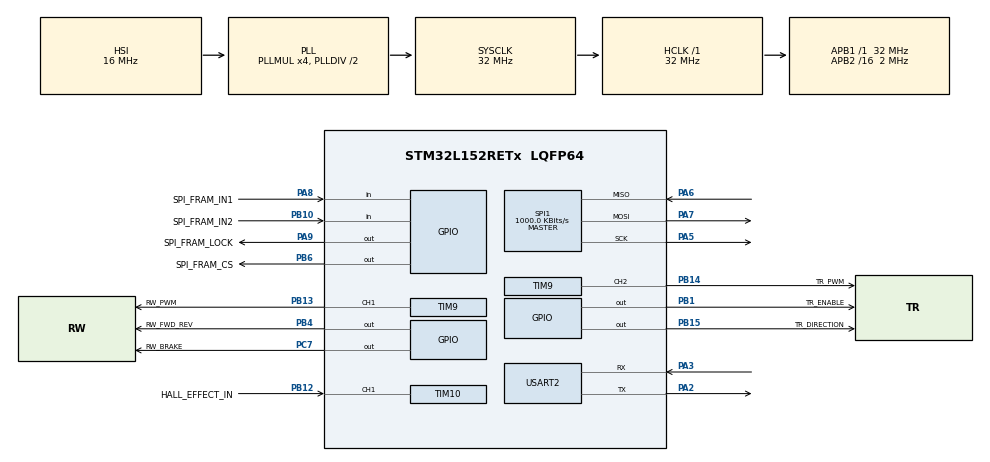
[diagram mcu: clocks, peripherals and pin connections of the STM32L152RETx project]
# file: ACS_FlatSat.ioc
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Mcu.Family=STM32L1
Mcu.Name=STM32L152RETx
Mcu.Package=LQFP64
NVIC.PriorityGroup=NVIC_PRIORITYGROUP_0
PA2.Mode=Asynchronous
PA2.Signal=USART2_TX
PA3.Mode=Asynchronous
PA3.Signal=USART2_RX
PA5.Mode=Full_Duplex_Master
PA5.Signal=SPI1_SCK
PA6.Mode=Full_Duplex_Master
PA6.Signal=SPI1_MISO
PA7.Mode=Full_Duplex_Master
PA7.Signal=SPI1_MOSI
PA8.GPIO_Label=SPI_FRAM_IN1
PA8.Signal=GPIO_Input
PA9.GPIO_Label=SPI_FRAM_LOCK
PA9.Signal=GPIO_Output
PB1.GPIO_Label=TR_ENABLE
PB1.Signal=GPIO_Output
PB10.GPIO_Label=SPI_FRAM_IN2
PB10.Signal=GPIO_Input
PB12.GPIO_Label=HALL_EFFECT_IN
PB12.Signal=S_TIM10_CH1
PB13.GPIO_Label=RW_PWM
PB13.Signal=S_TIM9_CH1
PB14.GPIO_Label=TR_PWM
PB14.Signal=S_TIM9_CH2
PB15.GPIO_Label=TR_DIRECTION
PB15.Signal=GPIO_Output
PB4.GPIO_Label=RW_FWD_REV
PB4.Signal=GPIO_Output
PB6.GPIO_Label=SPI_FRAM_CS
PB6.Signal=GPIO_Output
PC7.GPIO_Label=RW_BRAKE
PC7.Signal=GPIO_Output
ProjectManager.HeapSize=0x2000
ProjectManager.StackSize=0x400
ProjectManager.TargetToolchain=TrueSTUDIO
RCC.48MHZClocksFreq_Value=32000000
RCC.AHBFreq_Value=32000000
RCC.APB1Freq_Value=32000000
RCC.APB1TimFreq_Value=32000000
RCC.APB2CLKDivider=RCC_HCLK_DIV16
RCC.APB2Freq_Value=2000000
RCC.APB2TimFreq_Value=4000000
RCC.HCLKFreq_Value=32000000
RCC.HSE_VALUE=8000000
RCC.HSI_VALUE=16000000
RCC.LSE_VALUE=32768
RCC.MSI_VALUE=2097000
RCC.PLLMUL=RCC_PLL_MUL4
RCC.RTCClockSelectionVirtual=RCC_RTCCLKSOURCE_LSE
RCC.SYSCLKFreq_VALUE=32000000
RCC.SYSCLKSource=RCC_SYSCLKSOURCE_PLLCLK
RCC.USBOutput=48000000
RCC.VCOOutputFreq_Value=64000000
SH.S_TIM10_CH1.0=TIM10_CH1,Input_Capture1_from_TI1
SH.S_TIM9_CH1.0=TIM9_CH1,PWM Generation1 CH1
SH.S_TIM9_CH2.0=TIM9_CH2,PWM Generation2 CH2
SPI1.CalculateBaudRate=1000.0 KBits/s
SPI1.Direction=SPI_DIRECTION_2LINES
SPI1.Mode=SPI_MODE_MASTER
SPI1.VirtualType=VM_MASTER
TIM10.Channel=TIM_CHANNEL_1
TIM10.ClockDivision=TIM_CLOCKDIVISION_DIV4
TIM10.ICPolarity_CH1=TIM_INPUTCHANNELPOLARITY_BOTHEDGE
TIM10.Period=65535
TIM9.Channel-PWM\ Generation1\ CH1=TIM_CHANNEL_1
TIM9.Channel-PWM\ Generation2\ CH2=TIM_CHANNEL_2
TIM9.ClockDivision=TIM_CLOCKDIVISION_DIV4
TIM9.Period=1000
TIM9.Pulse-PWM\ Generation1\ CH1=0
TIM9.Pulse-PWM\ Generation2\ CH2=0
USART2.OverSampling=UART_OVERSAMPLING_16
USART2.VirtualMode=VM_ASYNC
VP_TIM10_VS_ClockSourceINT.Mode=Internal
VP_TIM9_VS_ClockSourceINT.Mode=Internal
board=NUCLEO-L152RE

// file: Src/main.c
/* USER CODE BEGIN Header */
/**
  ******************************************************************************
  * @file           : main.c
  * @brief          : Main program body
  ******************************************************************************
  * @attention
  *
  * <h2><center>&copy; Copyright (c) 2019 STMicroelectronics.
  * All rights reserved.</center></h2>
  *
  * This software component is licensed by ST under BSD 3-Clause license,
  * the "License"; You may not use this file except in compliance with the
  * License. You may obtain a copy of the License at:
  *                        opensource.org/licenses/BSD-3-Clause
  *
  ******************************************************************************
  */
/* USER CODE END Header */

#include "main.h"

/* USER CODE BEGIN Includes */
#include <ACSStateMachine.h>
#include <string.h>
/* USER CODE END Includes */

SPI_HandleTypeDef hspi1;

TIM_HandleTypeDef htim9;
TIM_HandleTypeDef htim10;

UART_HandleTypeDef huart2;

void SystemClock_Config(void);
static void MX_GPIO_Init(void);
static void MX_USART2_UART_Init(void);
static void MX_SPI1_Init(void);
static void MX_TIM9_Init(void);
static void MX_TIM10_Init(void);

int main(void)
{

  /* MCU Configuration--------------------------------------------------------*/

  /* Reset of all peripherals, Initializes the Flash interface and the Systick. */
  HAL_Init();

  /* Configure the system clock */
  SystemClock_Config();

  /* Initialize all configured peripherals */
  MX_GPIO_Init();
  MX_USART2_UART_Init();
  MX_SPI1_Init();
  MX_TIM9_Init();
  MX_TIM10_Init();
  /* USER CODE BEGIN 2 */

  #ifdef ENABLE_ACTUATORS
  initActuators(&htim9, &htim10);
  rw_init(RW_FWD_REV_Pin, RW_FWD_REV_GPIO_Port, RW_BRAKE_Pin, RW_BRAKE_GPIO_Port);
  tr_init(TR_DIRECTION_Pin, TR_DIRECTION_GPIO_Port, TR_ENABLE_Pin, TR_ENABLE_GPIO_Port);
  #endif
  #ifdef ENABLE_42
  setUartHandle(&huart2);
  #endif
  #ifdef ENABLE_FRAM
  setSpiHandle(&hspi1);
  #endif
  runACS();

  /* USER CODE END 2 */

  /* Infinite loop */
  while (1)
  {

  }
}

void SystemClock_Config(void)
{
  RCC_OscInitTypeDef RCC_OscInitStruct = {0};
  RCC_ClkInitTypeDef RCC_ClkInitStruct = {0};

  /** Configure the main internal regulator output voltage
  */
  __HAL_PWR_VOLTAGESCALING_CONFIG(PWR_REGULATOR_VOLTAGE_SCALE1);
  /** Initializes the CPU, AHB and APB busses clocks
  */
  RCC_OscInitStruct.OscillatorType = RCC_OSCILLATORTYPE_HSI;
  RCC_OscInitStruct.HSIState = RCC_HSI_ON;
  RCC_OscInitStruct.HSICalibrationValue = RCC_HSICALIBRATION_DEFAULT;
  RCC_OscInitStruct.PLL.PLLState = RCC_PLL_ON;
  RCC_OscInitStruct.PLL.PLLSource = RCC_PLLSOURCE_HSI;
  RCC_OscInitStruct.PLL.PLLMUL = RCC_PLL_MUL4;
  RCC_OscInitStruct.PLL.PLLDIV = RCC_PLL_DIV2;
  if (HAL_RCC_OscConfig(&RCC_OscInitStruct) != HAL_OK)
  {
    Error_Handler();
  }
  /** Initializes the CPU, AHB and APB busses clocks
  */
  RCC_ClkInitStruct.ClockType = RCC_CLOCKTYPE_HCLK|RCC_CLOCKTYPE_SYSCLK
                              |RCC_CLOCKTYPE_PCLK1|RCC_CLOCKTYPE_PCLK2;
  RCC_ClkInitStruct.SYSCLKSource = RCC_SYSCLKSOURCE_PLLCLK;
  RCC_ClkInitStruct.AHBCLKDivider = RCC_SYSCLK_DIV1;
  RCC_ClkInitStruct.APB1CLKDivider = RCC_HCLK_DIV1;
  RCC_ClkInitStruct.APB2CLKDivider = RCC_HCLK_DIV16;

  if (HAL_RCC_ClockConfig(&RCC_ClkInitStruct, FLASH_LATENCY_1) != HAL_OK)
  {
    Error_Handler();
  }
}

static void MX_SPI1_Init(void)
{

  /* SPI1 parameter configuration*/
  hspi1.Instance = SPI1;
  hspi1.Init.Mode = SPI_MODE_MASTER;
  hspi1.Init.Direction = SPI_DIRECTION_2LINES;
  hspi1.Init.DataSize = SPI_DATASIZE_8BIT;
  hspi1.Init.CLKPolarity = SPI_POLARITY_LOW;
  hspi1.Init.CLKPhase = SPI_PHASE_1EDGE;
  hspi1.Init.NSS = SPI_NSS_SOFT;
  hspi1.Init.BaudRatePrescaler = SPI_BAUDRATEPRESCALER_2;
  hspi1.Init.FirstBit = SPI_FIRSTBIT_MSB;
  hspi1.Init.TIMode = SPI_TIMODE_DISABLE;
  hspi1.Init.CRCCalculation = SPI_CRCCALCULATION_DISABLE;
  hspi1.Init.CRCPolynomial = 10;
  if (HAL_SPI_Init(&hspi1) != HAL_OK)
  {
    Error_Handler();
  }

}

static void MX_TIM9_Init(void)
{

  TIM_ClockConfigTypeDef sClockSourceConfig = {0};
  TIM_MasterConfigTypeDef sMasterConfig = {0};
  TIM_OC_InitTypeDef sConfigOC = {0};

  htim9.Instance = TIM9;
  htim9.Init.Prescaler = 0;
  htim9.Init.CounterMode = TIM_COUNTERMODE_UP;
  htim9.Init.Period = 1000;
  htim9.Init.ClockDivision = TIM_CLOCKDIVISION_DIV4;
  if (HAL_TIM_Base_Init(&htim9) != HAL_OK)
  {
    Error_Handler();
  }
  sClockSourceConfig.ClockSource = TIM_CLOCKSOURCE_INTERNAL;
  if (HAL_TIM_ConfigClockSource(&htim9, &sClockSourceConfig) != HAL_OK)
  {
    Error_Handler();
  }
  if (HAL_TIM_PWM_Init(&htim9) != HAL_OK)
  {
    Error_Handler();
  }
  sMasterConfig.MasterOutputTrigger = TIM_TRGO_RESET;
  sMasterConfig.MasterSlaveMode = TIM_MASTERSLAVEMODE_DISABLE;
  if (HAL_TIMEx_MasterConfigSynchronization(&htim9, &sMasterConfig) != HAL_OK)
  {
    Error_Handler();
  }
  sConfigOC.OCMode = TIM_OCMODE_PWM1;
  sConfigOC.Pulse = 0;
  sConfigOC.OCPolarity = TIM_OCPOLARITY_HIGH;
  sConfigOC.OCFastMode = TIM_OCFAST_DISABLE;
  if (HAL_TIM_PWM_ConfigChannel(&htim9, &sConfigOC, TIM_CHANNEL_1) != HAL_OK)
  {
    Error_Handler();
  }
  if (HAL_TIM_PWM_ConfigChannel(&htim9, &sConfigOC, TIM_CHANNEL_2) != HAL_OK)
  {
    Error_Handler();
  }
  HAL_TIM_MspPostInit(&htim9);

}

static void MX_TIM10_Init(void)
{

  TIM_ClockConfigTypeDef sClockSourceConfig = {0};
  TIM_IC_InitTypeDef sConfigIC = {0};

  htim10.Instance = TIM10;
  htim10.Init.Prescaler = 0;
  htim10.Init.CounterMode = TIM_COUNTERMODE_UP;
  htim10.Init.Period = 65535;
  htim10.Init.ClockDivision = TIM_CLOCKDIVISION_DIV4;
  if (HAL_TIM_Base_Init(&htim10) != HAL_OK)
  {
    Error_Handler();
  }
  sClockSourceConfig.ClockSource = TIM_CLOCKSOURCE_INTERNAL;
  if (HAL_TIM_ConfigClockSource(&htim10, &sClockSourceConfig) != HAL_OK)
  {
    Error_Handler();
  }
  if (HAL_TIM_IC_Init(&htim10) != HAL_OK)
  {
    Error_Handler();
  }
  sConfigIC.ICPolarity = TIM_INPUTCHANNELPOLARITY_BOTHEDGE;
  sConfigIC.ICSelection = TIM_ICSELECTION_DIRECTTI;
  sConfigIC.ICPrescaler = TIM_ICPSC_DIV1;
  sConfigIC.ICFilter = 0;
  if (HAL_TIM_IC_ConfigChannel(&htim10, &sConfigIC, TIM_CHANNEL_1) != HAL_OK)
  {
    Error_Handler();
  }

}

static void MX_USART2_UART_Init(void)
{

  huart2.Instance = USART2;
  huart2.Init.BaudRate = 115200;
  huart2.Init.WordLength = UART_WORDLENGTH_8B;
  huart2.Init.StopBits = UART_STOPBITS_1;
  huart2.Init.Parity = UART_PARITY_NONE;
  huart2.Init.Mode = UART_MODE_TX_RX;
  huart2.Init.HwFlowCtl = UART_HWCONTROL_NONE;
  huart2.Init.OverSampling = UART_OVERSAMPLING_16;
  if (HAL_UART_Init(&huart2) != HAL_OK)
  {
    Error_Handler();
  }

}

static void MX_GPIO_Init(void)
{
  GPIO_InitTypeDef GPIO_InitStruct = {0};

  /* GPIO Ports Clock Enable */
  __HAL_RCC_GPIOA_CLK_ENABLE();
  __HAL_RCC_GPIOB_CLK_ENABLE();
  __HAL_RCC_GPIOC_CLK_ENABLE();

  /*Configure GPIO pin Output Level */
  HAL_GPIO_WritePin(GPIOB, TR_ENABLE_Pin|TR_DIRECTION_Pin|RW_FWD_REV_Pin|SPI_FRAM_CS_Pin, GPIO_PIN_RESET);

  /*Configure GPIO pin Output Level */
  HAL_GPIO_WritePin(RW_BRAKE_GPIO_Port, RW_BRAKE_Pin, GPIO_PIN_RESET);

  /*Configure GPIO pin Output Level */
  HAL_GPIO_WritePin(SPI_FRAM_LOCK_GPIO_Port, SPI_FRAM_LOCK_Pin, GPIO_PIN_RESET);

  /*Configure GPIO pins : TR_ENABLE_Pin TR_DIRECTION_Pin RW_FWD_REV_Pin SPI_FRAM_CS_Pin */
  GPIO_InitStruct.Pin = TR_ENABLE_Pin|TR_DIRECTION_Pin|RW_FWD_REV_Pin|SPI_FRAM_CS_Pin;
  GPIO_InitStruct.Mode = GPIO_MODE_OUTPUT_PP;
  GPIO_InitStruct.Pull = GPIO_NOPULL;
  GPIO_InitStruct.Speed = GPIO_SPEED_FREQ_LOW;
  HAL_GPIO_Init(GPIOB, &GPIO_InitStruct);

  /*Configure GPIO pin : SPI_FRAM_IN2_Pin */
  GPIO_InitStruct.Pin = SPI_FRAM_IN2_Pin;
  GPIO_InitStruct.Mode = GPIO_MODE_INPUT;
  GPIO_InitStruct.Pull = GPIO_NOPULL;
  HAL_GPIO_Init(SPI_FRAM_IN2_GPIO_Port, &GPIO_InitStruct);

  /*Configure GPIO pin : RW_BRAKE_Pin */
  GPIO_InitStruct.Pin = RW_BRAKE_Pin;
  GPIO_InitStruct.Mode = GPIO_MODE_OUTPUT_PP;
  GPIO_InitStruct.Pull = GPIO_NOPULL;
  GPIO_InitStruct.Speed = GPIO_SPEED_FREQ_LOW;
  HAL_GPIO_Init(RW_BRAKE_GPIO_Port, &GPIO_InitStruct);

  /*Configure GPIO pin : SPI_FRAM_IN1_Pin */
  GPIO_InitStruct.Pin = SPI_FRAM_IN1_Pin;
  GPIO_InitStruct.Mode = GPIO_MODE_INPUT;
  GPIO_InitStruct.Pull = GPIO_NOPULL;
  HAL_GPIO_Init(SPI_FRAM_IN1_GPIO_Port, &GPIO_InitStruct);

  /*Configure GPIO pin : SPI_FRAM_LOCK_Pin */
  GPIO_InitStruct.Pin = SPI_FRAM_LOCK_Pin;
  GPIO_InitStruct.Mode = GPIO_MODE_OUTPUT_PP;
  GPIO_InitStruct.Pull = GPIO_NOPULL;
  GPIO_InitStruct.Speed = GPIO_SPEED_FREQ_LOW;
  HAL_GPIO_Init(SPI_FRAM_LOCK_GPIO_Port, &GPIO_InitStruct);

}

void Error_Handler(void)
{
}

/************************ (C) COPYRIGHT STMicroelectronics *****END OF FILE****/
